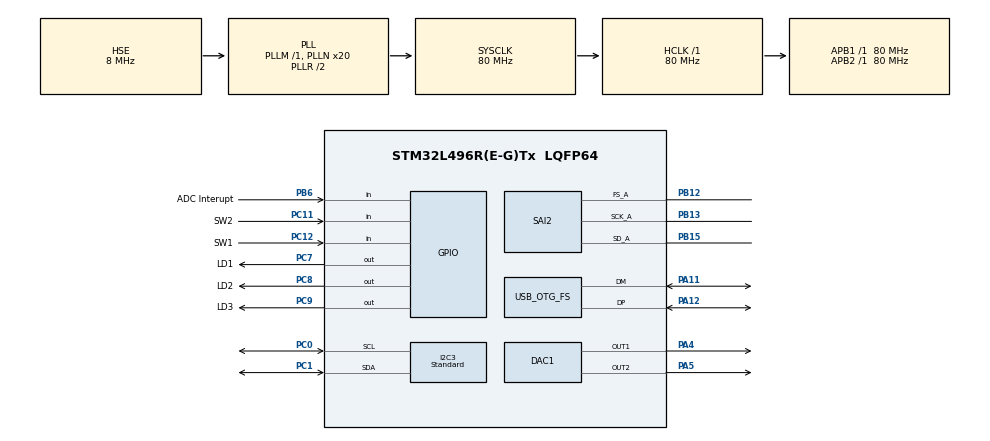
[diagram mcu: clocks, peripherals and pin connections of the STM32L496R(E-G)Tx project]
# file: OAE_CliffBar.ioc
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DAC1.DAC_Channel-DAC_OUT2=DAC_CHANNEL_2
DAC1.DAC_Trigger-DAC_OUT1=DAC_TRIGGER_T6_TRGO
DAC1.DAC_Trigger-DAC_OUT2=DAC_TRIGGER_T6_TRGO
Dma.DAC_CH1.0.Direction=DMA_MEMORY_TO_PERIPH
Dma.DAC_CH1.0.Instance=DMA1_Channel3
Dma.DAC_CH1.0.MemDataAlignment=DMA_MDATAALIGN_WORD
Dma.DAC_CH1.0.MemInc=DMA_MINC_ENABLE
Dma.DAC_CH1.0.Mode=DMA_CIRCULAR
Dma.DAC_CH1.0.PeriphDataAlignment=DMA_PDATAALIGN_WORD
Dma.DAC_CH1.0.PeriphInc=DMA_PINC_DISABLE
Dma.DAC_CH1.0.Priority=DMA_PRIORITY_HIGH
Dma.Request0=DAC_CH1
Dma.Request1=SAI2_A
Dma.SAI2_A.1.Direction=DMA_PERIPH_TO_MEMORY
Dma.SAI2_A.1.Instance=DMA1_Channel6
Dma.SAI2_A.1.MemDataAlignment=DMA_MDATAALIGN_HALFWORD
Dma.SAI2_A.1.MemInc=DMA_MINC_ENABLE
Dma.SAI2_A.1.Mode=DMA_CIRCULAR
Dma.SAI2_A.1.PeriphDataAlignment=DMA_PDATAALIGN_HALFWORD
Dma.SAI2_A.1.PeriphInc=DMA_PINC_DISABLE
Dma.SAI2_A.1.Priority=DMA_PRIORITY_HIGH
I2C3.AddressingMode=I2C_ADDRESSINGMODE_7BIT
I2C3.Analog_Filter=I2C_ANALOGFILTER_DISABLE
I2C3.CustomTiming=Disabled
I2C3.DualAddressMode=I2C_DUALADDRESS_DISABLE
I2C3.GeneralCallMode=I2C_GENERALCALL_DISABLE
I2C3.I2C_Coeff_DF=0
I2C3.I2C_Fall_Time=0
I2C3.I2C_Rise_Time=0
I2C3.I2C_Speed_Mode=I2C_Standard
I2C3.NoStretchMode=I2C_NOSTRETCH_DISABLE
I2C3.OwnAddress=0
I2C3.Speed=100
I2C3.Timing=0x10909EEE
Mcu.Family=STM32L4
Mcu.Name=STM32L496R(E-G)Tx
Mcu.Package=LQFP64
NVIC.DMA1_Channel3_IRQn=true\:0\:0\:false\:false\:true\:false\:true\:true
NVIC.DMA1_Channel6_IRQn=true\:0\:0\:false\:false\:true\:false\:true\:true
NVIC.I2C3_ER_IRQn=true\:0\:0\:false\:false\:true\:true\:true\:true
NVIC.I2C3_EV_IRQn=true\:0\:0\:false\:false\:true\:true\:true\:true
NVIC.OTG_FS_IRQn=true\:0\:0\:false\:false\:true\:false\:true\:true
NVIC.PriorityGroup=NVIC_PRIORITYGROUP_4
PA11.Mode=Device_Only
PA11.Signal=USB_OTG_FS_DM
PA12.Mode=Device_Only
PA12.Signal=USB_OTG_FS_DP
PA13\ (JTMS/SWDIO).Signal=SYS_JTMS-SWDIO
PA14\ (JTCK/SWCLK).Signal=SYS_JTCK-SWCLK
PA4.Signal=COMP_DAC11_group
PA5.Signal=COMP_DAC12_group
PB12.Mode=SAI_A_Master
PB12.Signal=SAI2_FS_A
PB13.Mode=SAI_A_Master
PB13.Signal=SAI2_SCK_A
PB14.Signal=SAI2_MCLK_A
PB15.Mode=SAI_A_Master
PB15.Signal=SAI2_SD_A
PB3\ (JTDO/TRACESWO).Signal=SYS_JTDO-SWO
PB6.GPIO_Label=ADC Interupt
PB6.Signal=GPIO_Input
PC0.GPIO_Pu=GPIO_PULLUP
PC0.GPIO_Speed=GPIO_SPEED_FREQ_VERY_HIGH
PC0.Mode=I2C
PC0.Signal=I2C3_SCL
PC1.GPIO_Pu=GPIO_PULLUP
PC1.Mode=I2C
PC1.Signal=I2C3_SDA
PC11.GPIO_Label=SW2
PC11.Signal=GPIO_Input
PC12.GPIO_Label=SW1
PC12.GPIO_PuPd=GPIO_NOPULL
PC12.Signal=GPIO_Input
PC5.GPIO_Label=MSC
PC5.Signal=ADCx_IN14
PC7.GPIO_Label=LD1
PC7.Signal=GPIO_Output
PC8.GPIO_Label=LD2
PC8.Signal=GPIO_Output
PC9.GPIO_Label=LD3
PC9.Signal=GPIO_Output
PH0-OSC_IN\ (PH0).Mode=HSE-External-Oscillator
PH0-OSC_IN\ (PH0).Signal=RCC_OSC_IN
PH1-OSC_OUT\ (PH1).Mode=HSE-External-Oscillator
PH1-OSC_OUT\ (PH1).Signal=RCC_OSC_OUT
ProjectManager.HeapSize=0x200
ProjectManager.StackSize=0x400
ProjectManager.TargetToolchain=STM32CubeIDE
RCC.ADCFreq_Value=48000000
RCC.AHBFreq_Value=80000000
RCC.APB1Freq_Value=80000000
RCC.APB1TimFreq_Value=80000000
RCC.APB2Freq_Value=80000000
RCC.APB2TimFreq_Value=80000000
RCC.CortexFreq_Value=80000000
RCC.FLatency=FLASH_LATENCY_4
RCC.HCLKFreq_Value=80000000
RCC.HSE_VALUE=8000000
RCC.HSI48_VALUE=48000000
RCC.HSICalibrationValue=16
RCC.HSI_VALUE=16000000
RCC.LSE_VALUE=32768
RCC.MSI_VALUE=4000000
RCC.PLLN=20
RCC.PLLSAI1N=12
RCC.PLLSourceVirtual=RCC_PLLSOURCE_HSE
RCC.SYSCLKFreq_VALUE=80000000
RCC.SYSCLKSource=RCC_SYSCLKSOURCE_PLLCLK
RCC.USBFreq_Value=48000000
RCC.VCOOutputFreq_Value=160000000
SAI2.AudioFrequency-SAI_A_Master=SAI_AUDIO_FREQUENCY_48K
SAI2.AudioMode-SAI_A_Master=SAI_MODEMASTER_RX
SAI2.BasicDataSize-SAI_A_Master=SAI_PROTOCOL_DATASIZE_24BIT
SAI2.BasicProtocol-SAI_A_Master=SAI_I2S_STANDARD
SAI2.BasicSlotNumber-SAI_A_Master=2
SAI2.CompandingMode-SAI_A_Master=SAI_NOCOMPANDING
SAI2.ErrorAudioFreq-SAI_A_Master=-2.34 %
SAI2.FIFOThreshold-SAI_A_Master=SAI_FIFOTHRESHOLD_EMPTY
SAI2.InitProtocol-SAI_A_Master=Enable
SAI2.Instance-SAI_A_Master=SAI$Index_Block_A
SAI2.MClockEnable-SAI_A_Master=SAI_MASTERCLOCK_DISABLE
SAI2.MonoStereoMode-SAI_A_Master=SAI_STEREOMODE
SAI2.NoDivider-SAI_A_Master=SAI_MASTERDIVIDER_ENABLE
SAI2.OutputDrive-SAI_A_Master=SAI_OUTPUTDRIVE_DISABLE
SAI2.RealAudioFreq-SAI_A_Master=46.875 KHz
SAI2.Synchro_A=SAI_ASYNCHRONOUS
SAI2.VirtualMode-SAI_A_Master=VM_MASTER
SAI2.VirtualProtocol-SAI_A_BASIC=VM_BASIC_PROTOCOL
SH.ADCx_IN14.0=ADC1_IN14
SH.COMP_DAC11_group.0=DAC1_OUT1,DAC_OUT1
SH.COMP_DAC12_group.0=DAC1_OUT2,DAC_OUT2
STMicroelectronics.X-CUBE-TOUCHGFX.4.26.0_IsPackSelfContextualization=true
TIM6.AutoReloadPreload=TIM_AUTORELOAD_PRELOAD_DISABLE
TIM6.CounterMode=TIM_COUNTERMODE_UP
TIM6.Period=624
TIM6.Prescaler=0
TIM6.TIM_MasterOutputTrigger=TIM_TRGO_UPDATE
USB_DEVICE.CLASS_NAME_FS=CDC
USB_DEVICE.VirtualMode=Cdc
USB_DEVICE.VirtualModeFS=Cdc_FS
USB_OTG_FS.VirtualMode=Device_Only
VP_DMA2D_VS_DMA2D.Mode=DMA2D_Activate
VP_SAI2_VP_$IpInstance_SAIA_SAI_BASIC.Mode=SAI_A_BASIC
VP_TIM6_VS_ClockSourceINT.Mode=Enable_Timer
VP_USB_DEVICE_VS_USB_DEVICE_CDC_FS.Mode=CDC_FS
board=custom

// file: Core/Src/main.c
/* USER CODE BEGIN Header */
/**
  ******************************************************************************
  * @file           : main.c
  * @brief          : Main program body
  ******************************************************************************
  * @attention
  *
  * Copyright (c) 2023 STMicroelectronics.
  * All rights reserved.
  *
  * This software is licensed under terms that can be found in the LICENSE file
  * in the root directory of this software component.
  * If no LICENSE file comes with this software, it is provided AS-IS.
  *
  ******************************************************************************
  */
/* USER CODE END Header */
#include "main.h"
#include "usb_device.h"

DAC_HandleTypeDef hdac1;
DMA_HandleTypeDef hdma_dac_ch1;

DMA2D_HandleTypeDef hdma2d;

I2C_HandleTypeDef hi2c3;

SAI_HandleTypeDef hsai_BlockA2;
DMA_HandleTypeDef hdma_sai2_a;

TIM_HandleTypeDef htim6;

void SystemClock_Config(void);
void PeriphCommonClock_Config(void);
static void MX_GPIO_Init(void);
static void MX_DMA_Init(void);
static void MX_DAC1_Init(void);
static void MX_TIM6_Init(void);
static void MX_I2C3_Init(void);
static void MX_SAI2_Init(void);
static void MX_DMA2D_Init(void);

int main(void)
{

  /* USER CODE BEGIN 1 */
  // Debug freeze
  __HAL_DBGMCU_UNFREEZE_IWDG();
  /* USER CODE END 1 */

  /* MCU Configuration--------------------------------------------------------*/

  /* Reset of all peripherals, Initializes the Flash interface and the Systick. */
  HAL_Init();

  /* Configure the system clock */
  SystemClock_Config();

  /* Configure the peripherals common clocks */
  PeriphCommonClock_Config();

  /* Initialize all configured peripherals */
  MX_GPIO_Init();
  MX_DMA_Init();
  MX_DAC1_Init();
  MX_TIM6_Init();
  MX_I2C3_Init();
  MX_SAI2_Init();
  MX_USB_DEVICE_Init();
  MX_DMA2D_Init();
  /* USER CODE BEGIN 2 */
  app_setup();
  /* USER CODE END 2 */

  /* Infinite loop */
  while (1)
  {

    /* USER CODE BEGIN 3 */
    app_loop();
  }
  /* USER CODE END 3 */
}

void SystemClock_Config(void)
{
  RCC_OscInitTypeDef RCC_OscInitStruct = {0};
  RCC_ClkInitTypeDef RCC_ClkInitStruct = {0};

  /** Configure the main internal regulator output voltage
  */
  if (HAL_PWREx_ControlVoltageScaling(PWR_REGULATOR_VOLTAGE_SCALE1) != HAL_OK)
  {
    Error_Handler();
  }

  /** Initializes the RCC Oscillators according to the specified parameters
  * in the RCC_OscInitTypeDef structure.
  */
  RCC_OscInitStruct.OscillatorType = RCC_OSCILLATORTYPE_HSE;
  RCC_OscInitStruct.HSEState = RCC_HSE_ON;
  RCC_OscInitStruct.PLL.PLLState = RCC_PLL_ON;
  RCC_OscInitStruct.PLL.PLLSource = RCC_PLLSOURCE_HSE;
  RCC_OscInitStruct.PLL.PLLM = 1;
  RCC_OscInitStruct.PLL.PLLN = 20;
  RCC_OscInitStruct.PLL.PLLP = RCC_PLLP_DIV2;
  RCC_OscInitStruct.PLL.PLLQ = RCC_PLLQ_DIV2;
  RCC_OscInitStruct.PLL.PLLR = RCC_PLLR_DIV2;
  if (HAL_RCC_OscConfig(&RCC_OscInitStruct) != HAL_OK)
  {
    Error_Handler();
  }

  /** Initializes the CPU, AHB and APB buses clocks
  */
  RCC_ClkInitStruct.ClockType = RCC_CLOCKTYPE_HCLK|RCC_CLOCKTYPE_SYSCLK
                              |RCC_CLOCKTYPE_PCLK1|RCC_CLOCKTYPE_PCLK2;
  RCC_ClkInitStruct.SYSCLKSource = RCC_SYSCLKSOURCE_PLLCLK;
  RCC_ClkInitStruct.AHBCLKDivider = RCC_SYSCLK_DIV1;
  RCC_ClkInitStruct.APB1CLKDivider = RCC_HCLK_DIV1;
  RCC_ClkInitStruct.APB2CLKDivider = RCC_HCLK_DIV1;

  if (HAL_RCC_ClockConfig(&RCC_ClkInitStruct, FLASH_LATENCY_4) != HAL_OK)
  {
    Error_Handler();
  }
}

void PeriphCommonClock_Config(void)
{
  RCC_PeriphCLKInitTypeDef PeriphClkInit = {0};

  /** Initializes the peripherals clock
  */
  PeriphClkInit.PeriphClockSelection = RCC_PERIPHCLK_SAI2|RCC_PERIPHCLK_USB;
  PeriphClkInit.Sai2ClockSelection = RCC_SAI2CLKSOURCE_PLLSAI1;
  PeriphClkInit.UsbClockSelection = RCC_USBCLKSOURCE_PLLSAI1;
  PeriphClkInit.PLLSAI1.PLLSAI1Source = RCC_PLLSOURCE_HSE;
  PeriphClkInit.PLLSAI1.PLLSAI1M = 1;
  PeriphClkInit.PLLSAI1.PLLSAI1N = 12;
  PeriphClkInit.PLLSAI1.PLLSAI1P = RCC_PLLP_DIV2;
  PeriphClkInit.PLLSAI1.PLLSAI1Q = RCC_PLLQ_DIV2;
  PeriphClkInit.PLLSAI1.PLLSAI1R = RCC_PLLR_DIV2;
  PeriphClkInit.PLLSAI1.PLLSAI1ClockOut = RCC_PLLSAI1_SAI1CLK|RCC_PLLSAI1_48M2CLK;
  if (HAL_RCCEx_PeriphCLKConfig(&PeriphClkInit) != HAL_OK)
  {
    Error_Handler();
  }
}

static void MX_DAC1_Init(void)
{

  DAC_ChannelConfTypeDef sConfig = {0};

  /** DAC Initialization
  */
  hdac1.Instance = DAC1;
  if (HAL_DAC_Init(&hdac1) != HAL_OK)
  {
    Error_Handler();
  }

  /** DAC channel OUT1 config
  */
  sConfig.DAC_SampleAndHold = DAC_SAMPLEANDHOLD_DISABLE;
  sConfig.DAC_Trigger = DAC_TRIGGER_T6_TRGO;
  sConfig.DAC_OutputBuffer = DAC_OUTPUTBUFFER_ENABLE;
  sConfig.DAC_ConnectOnChipPeripheral = DAC_CHIPCONNECT_DISABLE;
  sConfig.DAC_UserTrimming = DAC_TRIMMING_FACTORY;
  if (HAL_DAC_ConfigChannel(&hdac1, &sConfig, DAC_CHANNEL_1) != HAL_OK)
  {
    Error_Handler();
  }

  /** DAC channel OUT2 config
  */
  if (HAL_DAC_ConfigChannel(&hdac1, &sConfig, DAC_CHANNEL_2) != HAL_OK)
  {
    Error_Handler();
  }

}

static void MX_DMA2D_Init(void)
{

  hdma2d.Instance = DMA2D;
  hdma2d.Init.Mode = DMA2D_M2M;
  hdma2d.Init.ColorMode = DMA2D_OUTPUT_ARGB8888;
  hdma2d.Init.OutputOffset = 0;
  hdma2d.LayerCfg[1].InputOffset = 0;
  hdma2d.LayerCfg[1].InputColorMode = DMA2D_INPUT_ARGB8888;
  hdma2d.LayerCfg[1].AlphaMode = DMA2D_NO_MODIF_ALPHA;
  hdma2d.LayerCfg[1].InputAlpha = 0;
  hdma2d.LayerCfg[1].AlphaInverted = DMA2D_REGULAR_ALPHA;
  hdma2d.LayerCfg[1].RedBlueSwap = DMA2D_RB_REGULAR;
  if (HAL_DMA2D_Init(&hdma2d) != HAL_OK)
  {
    Error_Handler();
  }
  if (HAL_DMA2D_ConfigLayer(&hdma2d, 1) != HAL_OK)
  {
    Error_Handler();
  }

}

static void MX_I2C3_Init(void)
{

  hi2c3.Instance = I2C3;
  hi2c3.Init.Timing = 0x10909EEE;
  hi2c3.Init.OwnAddress1 = 0;
  hi2c3.Init.AddressingMode = I2C_ADDRESSINGMODE_7BIT;
  hi2c3.Init.DualAddressMode = I2C_DUALADDRESS_DISABLE;
  hi2c3.Init.OwnAddress2 = 0;
  hi2c3.Init.OwnAddress2Masks = I2C_OA2_NOMASK;
  hi2c3.Init.GeneralCallMode = I2C_GENERALCALL_DISABLE;
  hi2c3.Init.NoStretchMode = I2C_NOSTRETCH_DISABLE;
  if (HAL_I2C_Init(&hi2c3) != HAL_OK)
  {
    Error_Handler();
  }

  /** Configure Analogue filter
  */
  if (HAL_I2CEx_ConfigAnalogFilter(&hi2c3, I2C_ANALOGFILTER_DISABLE) != HAL_OK)
  {
    Error_Handler();
  }

  /** Configure Digital filter
  */
  if (HAL_I2CEx_ConfigDigitalFilter(&hi2c3, 0) != HAL_OK)
  {
    Error_Handler();
  }

}

static void MX_SAI2_Init(void)
{

  hsai_BlockA2.Instance = SAI2_Block_A;
  hsai_BlockA2.Init.AudioMode = SAI_MODEMASTER_RX;
  hsai_BlockA2.Init.Synchro = SAI_ASYNCHRONOUS;
  hsai_BlockA2.Init.OutputDrive = SAI_OUTPUTDRIVE_DISABLE;
  hsai_BlockA2.Init.NoDivider = SAI_MASTERDIVIDER_ENABLE;
  hsai_BlockA2.Init.FIFOThreshold = SAI_FIFOTHRESHOLD_EMPTY;
  hsai_BlockA2.Init.AudioFrequency = SAI_AUDIO_FREQUENCY_48K;
  hsai_BlockA2.Init.SynchroExt = SAI_SYNCEXT_DISABLE;
  hsai_BlockA2.Init.MonoStereoMode = SAI_STEREOMODE;
  hsai_BlockA2.Init.CompandingMode = SAI_NOCOMPANDING;
  if (HAL_SAI_InitProtocol(&hsai_BlockA2, SAI_I2S_STANDARD, SAI_PROTOCOL_DATASIZE_24BIT, 2) != HAL_OK)
  {
    Error_Handler();
  }

}

static void MX_TIM6_Init(void)
{

  TIM_MasterConfigTypeDef sMasterConfig = {0};

  htim6.Instance = TIM6;
  htim6.Init.Prescaler = 0;
  htim6.Init.CounterMode = TIM_COUNTERMODE_UP;
  htim6.Init.Period = 624;
  htim6.Init.AutoReloadPreload = TIM_AUTORELOAD_PRELOAD_DISABLE;
  if (HAL_TIM_Base_Init(&htim6) != HAL_OK)
  {
    Error_Handler();
  }
  sMasterConfig.MasterOutputTrigger = TIM_TRGO_UPDATE;
  sMasterConfig.MasterSlaveMode = TIM_MASTERSLAVEMODE_DISABLE;
  if (HAL_TIMEx_MasterConfigSynchronization(&htim6, &sMasterConfig) != HAL_OK)
  {
    Error_Handler();
  }

}

static void MX_DMA_Init(void)
{

  /* DMA controller clock enable */
  __HAL_RCC_DMA1_CLK_ENABLE();

  /* DMA interrupt init */
  /* DMA1_Channel3_IRQn interrupt configuration */
  HAL_NVIC_SetPriority(DMA1_Channel3_IRQn, 0, 0);
  HAL_NVIC_EnableIRQ(DMA1_Channel3_IRQn);
  /* DMA1_Channel6_IRQn interrupt configuration */
  HAL_NVIC_SetPriority(DMA1_Channel6_IRQn, 0, 0);
  HAL_NVIC_EnableIRQ(DMA1_Channel6_IRQn);

}

static void MX_GPIO_Init(void)
{
  GPIO_InitTypeDef GPIO_InitStruct = {0};

  /* GPIO Ports Clock Enable */
  __HAL_RCC_GPIOH_CLK_ENABLE();
  __HAL_RCC_GPIOC_CLK_ENABLE();
  __HAL_RCC_GPIOA_CLK_ENABLE();
  __HAL_RCC_GPIOB_CLK_ENABLE();

  /*Configure GPIO pin Output Level */
  HAL_GPIO_WritePin(GPIOC, LD1_Pin|LD2_Pin|LD3_Pin, GPIO_PIN_RESET);

  /*Configure GPIO pin : MSC_Pin */
  GPIO_InitStruct.Pin = MSC_Pin;
  GPIO_InitStruct.Mode = GPIO_MODE_ANALOG;
  GPIO_InitStruct.Pull = GPIO_NOPULL;
  HAL_GPIO_Init(MSC_GPIO_Port, &GPIO_InitStruct);

  /*Configure GPIO pins : LD1_Pin LD2_Pin LD3_Pin */
  GPIO_InitStruct.Pin = LD1_Pin|LD2_Pin|LD3_Pin;
  GPIO_InitStruct.Mode = GPIO_MODE_OUTPUT_PP;
  GPIO_InitStruct.Pull = GPIO_NOPULL;
  GPIO_InitStruct.Speed = GPIO_SPEED_FREQ_LOW;
  HAL_GPIO_Init(GPIOC, &GPIO_InitStruct);

  /*Configure GPIO pins : SW2_Pin SW1_Pin */
  GPIO_InitStruct.Pin = SW2_Pin|SW1_Pin;
  GPIO_InitStruct.Mode = GPIO_MODE_INPUT;
  GPIO_InitStruct.Pull = GPIO_NOPULL;
  HAL_GPIO_Init(GPIOC, &GPIO_InitStruct);

  /*Configure GPIO pin : ADC_Interupt_Pin */
  GPIO_InitStruct.Pin = ADC_Interupt_Pin;
  GPIO_InitStruct.Mode = GPIO_MODE_INPUT;
  GPIO_InitStruct.Pull = GPIO_NOPULL;
  HAL_GPIO_Init(ADC_Interupt_GPIO_Port, &GPIO_InitStruct);

}

void Error_Handler(void)
{
  /* USER CODE BEGIN Error_Handler_Debug */
  /* User can add his own implementation to report the HAL error return state */
  __disable_irq();
  while (1)
  {
	  HAL_GPIO_TogglePin(LD3_GPIO_Port,LD3_Pin);
  }
  /* USER CODE END Error_Handler_Debug */
}
